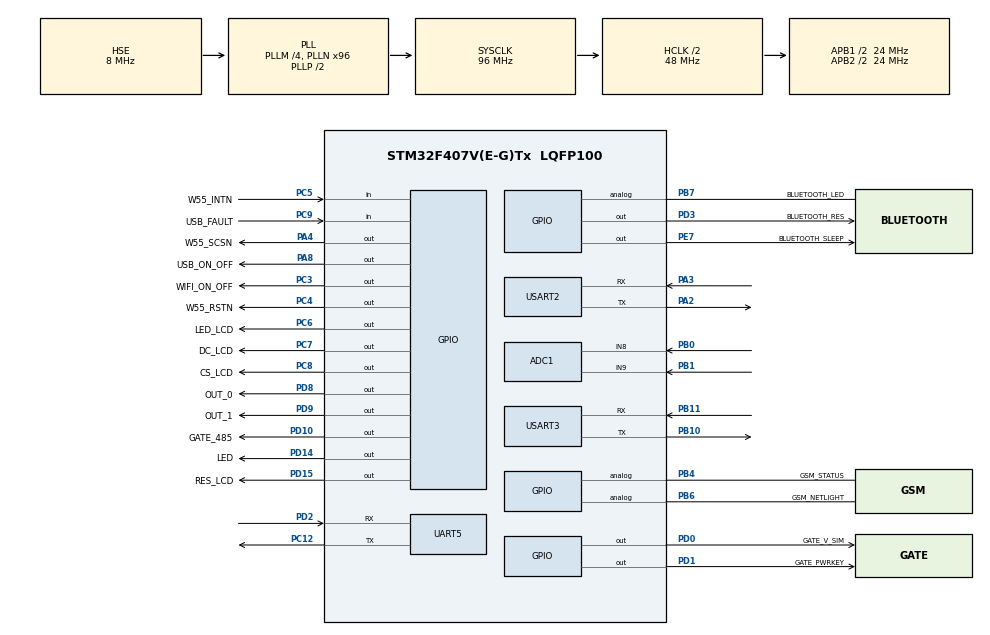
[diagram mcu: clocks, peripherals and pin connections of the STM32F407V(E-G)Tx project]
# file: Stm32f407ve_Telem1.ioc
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ADC1.Channel-1\#ChannelRegularConversion=ADC_CHANNEL_8
ADC1.NbrOfConversionFlag=1
ADC1.Rank-1\#ChannelRegularConversion=1
ADC1.SamplingTime-1\#ChannelRegularConversion=ADC_SAMPLETIME_3CYCLES
ADC1.master=1
Mcu.Family=STM32F4
Mcu.Name=STM32F407V(E-G)Tx
Mcu.Package=LQFP100
NVIC.PriorityGroup=NVIC_PRIORITYGROUP_4
NVIC.TIM2_IRQn=true\:0\:0\:false\:false\:true\:true\:true\:true
NVIC.USART3_IRQn=true\:0\:0\:false\:false\:true\:true\:true\:true
PA13.Mode=Serial_Wire
PA13.Signal=SYS_JTMS-SWDIO
PA14.Mode=Serial_Wire
PA14.Signal=SYS_JTCK-SWCLK
PA2.Mode=Asynchronous
PA2.Signal=USART2_TX
PA3.Mode=Asynchronous
PA3.Signal=USART2_RX
PA4.GPIO_Label=W55_SCSN
PA4.GPIO_Speed=GPIO_SPEED_FREQ_MEDIUM
PA4.Signal=GPIO_Output
PA8.GPIO_Label=USB_ON_OFF
PA8.Signal=GPIO_Output
PB0.Signal=ADCx_IN8
PB1.Signal=ADCx_IN9
PB10.Mode=Asynchronous
PB10.Signal=USART3_TX
PB11.Mode=Asynchronous
PB11.Signal=USART3_RX
PB4.GPIO_Label=GSM_STATUS
PB4.Signal=GPIO_Analog
PB6.GPIO_Label=GSM_NETLIGHT
PB6.GPIO_PuPd=GPIO_NOPULL
PB6.Signal=GPIO_Analog
PB7.GPIO_Label=BLUETOOTH_LED
PB7.Signal=GPIO_Analog
PC12.Mode=Asynchronous
PC12.Signal=UART5_TX
PC3.GPIO_Label=WIFI_ON_OFF
PC3.Signal=GPIO_Output
PC4.GPIO_Label=W55_RSTN
PC4.GPIO_Speed=GPIO_SPEED_FREQ_MEDIUM
PC4.Signal=GPIO_Output
PC5.GPIO_Label=W55_INTN
PC5.Signal=GPIO_Input
PC6.GPIO_Label=LED_LCD
PC6.Signal=GPIO_Output
PC7.GPIO_Label=DC_LCD
PC7.Signal=GPIO_Output
PC8.GPIO_Label=CS_LCD
PC8.Signal=GPIO_Output
PC9.GPIO_Label=USB_FAULT
PC9.Signal=GPIO_Input
PD0.GPIO_Label=GATE_V_SIM
PD0.GPIO_ModeDefaultOutputPP=GPIO_MODE_OUTPUT_OD
PD0.GPIO_PuPd=GPIO_NOPULL
PD0.PinState=GPIO_PIN_SET
PD0.Signal=GPIO_Output
PD1.GPIO_Label=GATE_PWRKEY
PD1.Signal=GPIO_Output
PD10.GPIO_Label=GATE_485
PD10.GPIO_ModeDefaultOutputPP=GPIO_MODE_OUTPUT_OD
PD10.GPIO_PuPd=GPIO_NOPULL
PD10.PinState=GPIO_PIN_SET
PD10.Signal=GPIO_Output
PD14.GPIO_Label=LED
PD14.PinState=GPIO_PIN_RESET
PD14.Signal=GPIO_Output
PD15.GPIO_Label=RES_LCD
PD15.Signal=GPIO_Output
PD2.Mode=Asynchronous
PD2.Signal=UART5_RX
PD3.GPIO_Label=BLUETOOTH_RES
PD3.PinState=GPIO_PIN_SET
PD3.Signal=GPIO_Output
PD8.GPIO_Label=OUT_0
PD8.Signal=GPIO_Output
PD9.GPIO_Label=OUT_1
PD9.Signal=GPIO_Output
PE7.GPIO_Label=BLUETOOTH_SLEEP
PE7.Signal=GPIO_Output
PH0-OSC_IN.Mode=HSE-External-Oscillator
PH0-OSC_IN.Signal=RCC_OSC_IN
PH1-OSC_OUT.Mode=HSE-External-Oscillator
PH1-OSC_OUT.Signal=RCC_OSC_OUT
ProjectManager.HeapSize=0x2000
ProjectManager.StackSize=0x4000
ProjectManager.TargetToolchain=STM32CubeIDE
RCC.48MHZClocksFreq_Value=27428571.42857143
RCC.AHBCLKDivider=RCC_SYSCLK_DIV2
RCC.AHBFreq_Value=48000000
RCC.APB1CLKDivider=RCC_HCLK_DIV2
RCC.APB1Freq_Value=24000000
RCC.APB1TimFreq_Value=48000000
RCC.APB2CLKDivider=RCC_HCLK_DIV2
RCC.APB2Freq_Value=24000000
RCC.APB2TimFreq_Value=48000000
RCC.CortexFreq_Value=48000000
RCC.HCLKFreq_Value=48000000
RCC.HSE_VALUE=8000000
RCC.HSI_VALUE=16000000
RCC.LSE_VALUE=32768
RCC.PLLM=4
RCC.PLLN=96
RCC.PLLQ=7
RCC.PLLSourceVirtual=RCC_PLLSOURCE_HSE
RCC.SYSCLKFreq_VALUE=96000000
RCC.SYSCLKSource=RCC_SYSCLKSOURCE_PLLCLK
RCC.VCOOutputFreq_Value=192000000
SH.ADCx_IN8.0=ADC1_IN8,IN8
SH.ADCx_IN9.0=ADC1_IN9,IN9
TIM2.Period=1000
TIM2.Prescaler=41999
UART5.VirtualMode=Asynchronous
USART2.VirtualMode=VM_ASYNC
USART3.VirtualMode=VM_ASYNC
VP_TIM2_VS_ClockSourceINT.Mode=Internal
board=custom

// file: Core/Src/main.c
/* USER CODE BEGIN Header */
/**
  ******************************************************************************
  * @file           : main.c
  * @brief          : Main program body
  ******************************************************************************
  * @attention
  *
  * Copyright (c) 2024 STMicroelectronics.
  * All rights reserved.
  *
  * This software is licensed under terms that can be found in the LICENSE file
  * in the root directory of this software component.
  * If no LICENSE file comes with this software, it is provided AS-IS.
  *
  ******************************************************************************
  */
/* USER CODE END Header */
#include "main.h"

ADC_HandleTypeDef hadc1;

TIM_HandleTypeDef htim2;

UART_HandleTypeDef huart5;
UART_HandleTypeDef huart2;
UART_HandleTypeDef huart3;

/* USER CODE BEGIN PV */

uint8_t rx_buff[BUFSIZE] = {0,};
uint8_t tx_buff[BUFSIZE] = {0,};
uint16_t rx_buff_len;

/* USER CODE END PV */

void SystemClock_Config(void);
static void MX_GPIO_Init(void);
static void MX_TIM2_Init(void);
static void MX_ADC1_Init(void);
static void MX_USART2_UART_Init(void);
static void MX_UART5_Init(void);
static void MX_USART3_UART_Init(void);

int main(void)
{

  /* MCU Configuration--------------------------------------------------------*/

  /* Reset of all peripherals, Initializes the Flash interface and the Systick. */
  HAL_Init();

  /* Configure the system clock */
  SystemClock_Config();

  /* Initialize all configured peripherals */
  MX_GPIO_Init();
  MX_TIM2_Init();
  MX_ADC1_Init();
  MX_USART2_UART_Init();
  MX_UART5_Init();
  MX_USART3_UART_Init();
  /* USER CODE BEGIN 2 */

  //Bluetooth on!
  HAL_GPIO_WritePin(BLUETOOTH_SLEEP_GPIO_Port, BLUETOOTH_SLEEP_Pin, GPIO_PIN_SET);

  //Bluetooth Reset!
  HAL_GPIO_WritePin(GPIOD, BLUETOOTH_RES_Pin, GPIO_PIN_RESET);
  HAL_Delay(1000);
  HAL_GPIO_WritePin(GPIOD, BLUETOOTH_RES_Pin, GPIO_PIN_SET);

  //ADUM and RS485 on!
  HAL_GPIO_WritePin(GPIOD, GATE_485_Pin, GPIO_PIN_RESET);

  //receive uart3
  __HAL_UART_ENABLE_IT(&huart3, UART_IT_IDLE);
  HAL_UART_Receive_IT(&huart3, (uint8_t*)rx_buff, BUFSIZE);

  /* USER CODE END 2 */

  /* Infinite loop */
  while (1)
  {

    /* USER CODE BEGIN 3 */
	  HAL_GPIO_WritePin(LED_GPIO_Port, LED_Pin, GPIO_PIN_RESET);
	  HAL_Delay(1000);
	  HAL_GPIO_WritePin(LED_GPIO_Port, LED_Pin, GPIO_PIN_SET);
	  HAL_Delay(1000);

	  //HAL_UART_Transmit(&huart3, str, 6, 1000);
	  //HAL_UART_Transmit(&huart5, str, 6, 1000);
  }
  /* USER CODE END 3 */
}

void SystemClock_Config(void)
{
  RCC_OscInitTypeDef RCC_OscInitStruct = {0};
  RCC_ClkInitTypeDef RCC_ClkInitStruct = {0};

  /** Configure the main internal regulator output voltage
  */
  __HAL_RCC_PWR_CLK_ENABLE();
  __HAL_PWR_VOLTAGESCALING_CONFIG(PWR_REGULATOR_VOLTAGE_SCALE1);

  /** Initializes the RCC Oscillators according to the specified parameters
  * in the RCC_OscInitTypeDef structure.
  */
  RCC_OscInitStruct.OscillatorType = RCC_OSCILLATORTYPE_HSE;
  RCC_OscInitStruct.HSEState = RCC_HSE_ON;
  RCC_OscInitStruct.PLL.PLLState = RCC_PLL_ON;
  RCC_OscInitStruct.PLL.PLLSource = RCC_PLLSOURCE_HSE;
  RCC_OscInitStruct.PLL.PLLM = 4;
  RCC_OscInitStruct.PLL.PLLN = 96;
  RCC_OscInitStruct.PLL.PLLP = RCC_PLLP_DIV2;
  RCC_OscInitStruct.PLL.PLLQ = 7;
  if (HAL_RCC_OscConfig(&RCC_OscInitStruct) != HAL_OK)
  {
    Error_Handler();
  }

  /** Initializes the CPU, AHB and APB buses clocks
  */
  RCC_ClkInitStruct.ClockType = RCC_CLOCKTYPE_HCLK|RCC_CLOCKTYPE_SYSCLK
                              |RCC_CLOCKTYPE_PCLK1|RCC_CLOCKTYPE_PCLK2;
  RCC_ClkInitStruct.SYSCLKSource = RCC_SYSCLKSOURCE_PLLCLK;
  RCC_ClkInitStruct.AHBCLKDivider = RCC_SYSCLK_DIV2;
  RCC_ClkInitStruct.APB1CLKDivider = RCC_HCLK_DIV2;
  RCC_ClkInitStruct.APB2CLKDivider = RCC_HCLK_DIV2;

  if (HAL_RCC_ClockConfig(&RCC_ClkInitStruct, FLASH_LATENCY_1) != HAL_OK)
  {
    Error_Handler();
  }
}

static void MX_ADC1_Init(void)
{

  ADC_ChannelConfTypeDef sConfig = {0};

  /** Configure the global features of the ADC (Clock, Resolution, Data Alignment and number of conversion)
  */
  hadc1.Instance = ADC1;
  hadc1.Init.ClockPrescaler = ADC_CLOCK_SYNC_PCLK_DIV2;
  hadc1.Init.Resolution = ADC_RESOLUTION_12B;
  hadc1.Init.ScanConvMode = DISABLE;
  hadc1.Init.ContinuousConvMode = DISABLE;
  hadc1.Init.DiscontinuousConvMode = DISABLE;
  hadc1.Init.ExternalTrigConvEdge = ADC_EXTERNALTRIGCONVEDGE_NONE;
  hadc1.Init.ExternalTrigConv = ADC_SOFTWARE_START;
  hadc1.Init.DataAlign = ADC_DATAALIGN_RIGHT;
  hadc1.Init.NbrOfConversion = 1;
  hadc1.Init.DMAContinuousRequests = DISABLE;
  hadc1.Init.EOCSelection = ADC_EOC_SINGLE_CONV;
  if (HAL_ADC_Init(&hadc1) != HAL_OK)
  {
    Error_Handler();
  }

  /** Configure for the selected ADC regular channel its corresponding rank in the sequencer and its sample time.
  */
  sConfig.Channel = ADC_CHANNEL_8;
  sConfig.Rank = 1;
  sConfig.SamplingTime = ADC_SAMPLETIME_3CYCLES;
  if (HAL_ADC_ConfigChannel(&hadc1, &sConfig) != HAL_OK)
  {
    Error_Handler();
  }

}

static void MX_TIM2_Init(void)
{

  TIM_ClockConfigTypeDef sClockSourceConfig = {0};
  TIM_MasterConfigTypeDef sMasterConfig = {0};

  htim2.Instance = TIM2;
  htim2.Init.Prescaler = 41999;
  htim2.Init.CounterMode = TIM_COUNTERMODE_UP;
  htim2.Init.Period = 1000;
  htim2.Init.ClockDivision = TIM_CLOCKDIVISION_DIV1;
  htim2.Init.AutoReloadPreload = TIM_AUTORELOAD_PRELOAD_DISABLE;
  if (HAL_TIM_Base_Init(&htim2) != HAL_OK)
  {
    Error_Handler();
  }
  sClockSourceConfig.ClockSource = TIM_CLOCKSOURCE_INTERNAL;
  if (HAL_TIM_ConfigClockSource(&htim2, &sClockSourceConfig) != HAL_OK)
  {
    Error_Handler();
  }
  sMasterConfig.MasterOutputTrigger = TIM_TRGO_RESET;
  sMasterConfig.MasterSlaveMode = TIM_MASTERSLAVEMODE_DISABLE;
  if (HAL_TIMEx_MasterConfigSynchronization(&htim2, &sMasterConfig) != HAL_OK)
  {
    Error_Handler();
  }

}

static void MX_UART5_Init(void)
{

  huart5.Instance = UART5;
  huart5.Init.BaudRate = 115200;
  huart5.Init.WordLength = UART_WORDLENGTH_8B;
  huart5.Init.StopBits = UART_STOPBITS_1;
  huart5.Init.Parity = UART_PARITY_NONE;
  huart5.Init.Mode = UART_MODE_TX_RX;
  huart5.Init.HwFlowCtl = UART_HWCONTROL_NONE;
  huart5.Init.OverSampling = UART_OVERSAMPLING_16;
  if (HAL_UART_Init(&huart5) != HAL_OK)
  {
    Error_Handler();
  }

}

static void MX_USART2_UART_Init(void)
{

  huart2.Instance = USART2;
  huart2.Init.BaudRate = 115200;
  huart2.Init.WordLength = UART_WORDLENGTH_8B;
  huart2.Init.StopBits = UART_STOPBITS_1;
  huart2.Init.Parity = UART_PARITY_NONE;
  huart2.Init.Mode = UART_MODE_TX_RX;
  huart2.Init.HwFlowCtl = UART_HWCONTROL_NONE;
  huart2.Init.OverSampling = UART_OVERSAMPLING_16;
  if (HAL_UART_Init(&huart2) != HAL_OK)
  {
    Error_Handler();
  }

}

static void MX_USART3_UART_Init(void)
{

  huart3.Instance = USART3;
  huart3.Init.BaudRate = 115200;
  huart3.Init.WordLength = UART_WORDLENGTH_8B;
  huart3.Init.StopBits = UART_STOPBITS_1;
  huart3.Init.Parity = UART_PARITY_NONE;
  huart3.Init.Mode = UART_MODE_TX_RX;
  huart3.Init.HwFlowCtl = UART_HWCONTROL_NONE;
  huart3.Init.OverSampling = UART_OVERSAMPLING_16;
  if (HAL_UART_Init(&huart3) != HAL_OK)
  {
    Error_Handler();
  }

}

static void MX_GPIO_Init(void)
{
  GPIO_InitTypeDef GPIO_InitStruct = {0};

  /* GPIO Ports Clock Enable */
  __HAL_RCC_GPIOH_CLK_ENABLE();
  __HAL_RCC_GPIOC_CLK_ENABLE();
  __HAL_RCC_GPIOA_CLK_ENABLE();
  __HAL_RCC_GPIOB_CLK_ENABLE();
  __HAL_RCC_GPIOE_CLK_ENABLE();
  __HAL_RCC_GPIOD_CLK_ENABLE();

  /*Configure GPIO pin Output Level */
  HAL_GPIO_WritePin(GPIOC, WIFI_ON_OFF_Pin|W55_RSTN_Pin|LED_LCD_Pin|DC_LCD_Pin
                          |CS_LCD_Pin, GPIO_PIN_RESET);

  /*Configure GPIO pin Output Level */
  HAL_GPIO_WritePin(GPIOA, W55_SCSN_Pin|USB_ON_OFF_Pin, GPIO_PIN_RESET);

  /*Configure GPIO pin Output Level */
  HAL_GPIO_WritePin(BLUETOOTH_SLEEP_GPIO_Port, BLUETOOTH_SLEEP_Pin, GPIO_PIN_RESET);

  /*Configure GPIO pin Output Level */
  HAL_GPIO_WritePin(GPIOD, OUT_0_Pin|OUT_1_Pin|LED_Pin|RES_LCD_Pin
                          |GATE_PWRKEY_Pin, GPIO_PIN_RESET);

  /*Configure GPIO pin Output Level */
  HAL_GPIO_WritePin(GPIOD, GATE_485_Pin|GATE_V_SIM_Pin|BLUETOOTH_RES_Pin, GPIO_PIN_SET);

  /*Configure GPIO pins : WIFI_ON_OFF_Pin LED_LCD_Pin DC_LCD_Pin CS_LCD_Pin */
  GPIO_InitStruct.Pin = WIFI_ON_OFF_Pin|LED_LCD_Pin|DC_LCD_Pin|CS_LCD_Pin;
  GPIO_InitStruct.Mode = GPIO_MODE_OUTPUT_PP;
  GPIO_InitStruct.Pull = GPIO_NOPULL;
  GPIO_InitStruct.Speed = GPIO_SPEED_FREQ_LOW;
  HAL_GPIO_Init(GPIOC, &GPIO_InitStruct);

  /*Configure GPIO pin : W55_SCSN_Pin */
  GPIO_InitStruct.Pin = W55_SCSN_Pin;
  GPIO_InitStruct.Mode = GPIO_MODE_OUTPUT_PP;
  GPIO_InitStruct.Pull = GPIO_NOPULL;
  GPIO_InitStruct.Speed = GPIO_SPEED_FREQ_MEDIUM;
  HAL_GPIO_Init(W55_SCSN_GPIO_Port, &GPIO_InitStruct);

  /*Configure GPIO pin : W55_RSTN_Pin */
  GPIO_InitStruct.Pin = W55_RSTN_Pin;
  GPIO_InitStruct.Mode = GPIO_MODE_OUTPUT_PP;
  GPIO_InitStruct.Pull = GPIO_NOPULL;
  GPIO_InitStruct.Speed = GPIO_SPEED_FREQ_MEDIUM;
  HAL_GPIO_Init(W55_RSTN_GPIO_Port, &GPIO_InitStruct);

  /*Configure GPIO pins : W55_INTN_Pin USB_FAULT_Pin */
  GPIO_InitStruct.Pin = W55_INTN_Pin|USB_FAULT_Pin;
  GPIO_InitStruct.Mode = GPIO_MODE_INPUT;
  GPIO_InitStruct.Pull = GPIO_NOPULL;
  HAL_GPIO_Init(GPIOC, &GPIO_InitStruct);

  /*Configure GPIO pin : BLUETOOTH_SLEEP_Pin */
  GPIO_InitStruct.Pin = BLUETOOTH_SLEEP_Pin;
  GPIO_InitStruct.Mode = GPIO_MODE_OUTPUT_PP;
  GPIO_InitStruct.Pull = GPIO_NOPULL;
  GPIO_InitStruct.Speed = GPIO_SPEED_FREQ_LOW;
  HAL_GPIO_Init(BLUETOOTH_SLEEP_GPIO_Port, &GPIO_InitStruct);

  /*Configure GPIO pins : OUT_0_Pin OUT_1_Pin LED_Pin RES_LCD_Pin
                           GATE_PWRKEY_Pin BLUETOOTH_RES_Pin */
  GPIO_InitStruct.Pin = OUT_0_Pin|OUT_1_Pin|LED_Pin|RES_LCD_Pin
                          |GATE_PWRKEY_Pin|BLUETOOTH_RES_Pin;
  GPIO_InitStruct.Mode = GPIO_MODE_OUTPUT_PP;
  GPIO_InitStruct.Pull = GPIO_NOPULL;
  GPIO_InitStruct.Speed = GPIO_SPEED_FREQ_LOW;
  HAL_GPIO_Init(GPIOD, &GPIO_InitStruct);

  /*Configure GPIO pins : GATE_485_Pin GATE_V_SIM_Pin */
  GPIO_InitStruct.Pin = GATE_485_Pin|GATE_V_SIM_Pin;
  GPIO_InitStruct.Mode = GPIO_MODE_OUTPUT_OD;
  GPIO_InitStruct.Pull = GPIO_NOPULL;
  GPIO_InitStruct.Speed = GPIO_SPEED_FREQ_LOW;
  HAL_GPIO_Init(GPIOD, &GPIO_InitStruct);

  /*Configure GPIO pin : USB_ON_OFF_Pin */
  GPIO_InitStruct.Pin = USB_ON_OFF_Pin;
  GPIO_InitStruct.Mode = GPIO_MODE_OUTPUT_PP;
  GPIO_InitStruct.Pull = GPIO_NOPULL;
  GPIO_InitStruct.Speed = GPIO_SPEED_FREQ_LOW;
  HAL_GPIO_Init(USB_ON_OFF_GPIO_Port, &GPIO_InitStruct);

  /*Configure GPIO pins : GSM_STATUS_Pin GSM_NETLIGHT_Pin BLUETOOTH_LED_Pin */
  GPIO_InitStruct.Pin = GSM_STATUS_Pin|GSM_NETLIGHT_Pin|BLUETOOTH_LED_Pin;
  GPIO_InitStruct.Mode = GPIO_MODE_ANALOG;
  GPIO_InitStruct.Pull = GPIO_NOPULL;
  HAL_GPIO_Init(GPIOB, &GPIO_InitStruct);

}

void Error_Handler(void)
{
  __disable_irq();
  while (1)
  {
  }
}
